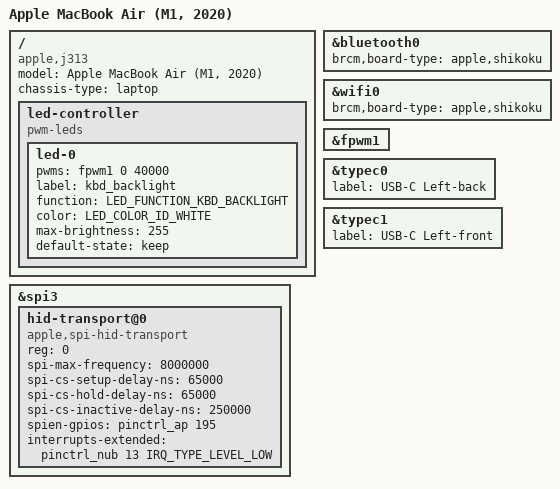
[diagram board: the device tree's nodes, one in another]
// SPDX-License-Identifier: GPL-2.0+ OR MIT
/*
 * Apple MacBook Air (M1, 2020)
 *
 * target-type: J313
 *
 * Copyright The Asahi Linux Contributors
 */

/dts-v1/;

#include "t8103.dtsi"
#include "t8103-jxxx.dtsi"
#include <dt-bindings/leds/common.h>

/ {
	compatible = "apple,j313", "apple,t8103", "apple,arm-platform";
	model = "Apple MacBook Air (M1, 2020)";
	chassis-type = "laptop";

	led-controller {
		compatible = "pwm-leds";
		led-0 {
			pwms = <&fpwm1 0 40000>;
			label = "kbd_backlight";
			function = LED_FUNCTION_KBD_BACKLIGHT;
			color = <LED_COLOR_ID_WHITE>;
			max-brightness = <255>;
			default-state = "keep";
		};
	};
};

&bluetooth0 {
	brcm,board-type = "apple,shikoku";
};

&wifi0 {
	brcm,board-type = "apple,shikoku";
};

&fpwm1 {
	status = "okay";
};

/*
 * Provide labels for the USB type C ports.
 */

&typec0 {
	label = "USB-C Left-back";
};

&typec1 {
	label = "USB-C Left-front";
};

&spi3 {
	status = "okay";

	hid-transport@0 {
		compatible = "apple,spi-hid-transport";
		reg = <0>;
		spi-max-frequency = <8000000>;
		/*
		 * Apple's ADT specifies 20us CS change delays, and the
		 * SPI HID interface metadata specifies 45us. Using either
		 * seems not to be reliable, but adding both works, so
		 * best guess is they are cumulative.
		 */
		spi-cs-setup-delay-ns = <65000>;
		spi-cs-hold-delay-ns = <65000>;
		spi-cs-inactive-delay-ns = <250000>;
		spien-gpios = <&pinctrl_ap 195 0>;
		interrupts-extended = <&pinctrl_nub 13 IRQ_TYPE_LEVEL_LOW>;
	};
};

#include "hwmon-laptop.dtsi"
